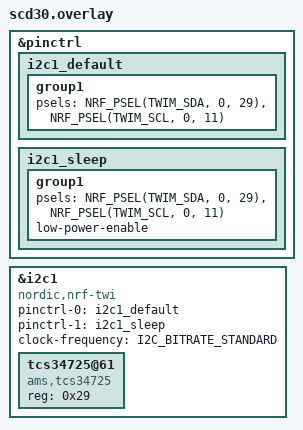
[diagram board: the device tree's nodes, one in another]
/*
 * Copyright (c) 2023 LSI-TEC
 *
 * SPDX-License-Identifier: Apache-2.0
 */

&pinctrl {
	i2c1_default: i2c1_default {
		group1 {
			psels = <NRF_PSEL(TWIM_SDA, 0, 29)>, // Verificar depois esses pinos
			        <NRF_PSEL(TWIM_SCL, 0, 11)>;
		};
	};

	i2c1_sleep: i2c1_sleep {
		group1 {
			psels = <NRF_PSEL(TWIM_SDA, 0, 29)>, 
			        <NRF_PSEL(TWIM_SCL, 0, 11)>;
			low-power-enable;
		};
	};
};

&i2c1 {
	compatible = "nordic,nrf-twi";
	status = "okay";

	pinctrl-0 = <&i2c1_default>;
	pinctrl-1 = <&i2c1_sleep>;
	pinctrl-names = "default", "sleep";

	clock-frequency = <I2C_BITRATE_STANDARD>;

	/* Color sensor */
	tcs34725@61 {
		compatible = "ams,tcs34725";
		reg = <0x29>;   /* Address of sensor */ // Verificar depois esse endereço // No codigo é feito 0x29 << 1 
		status = "okay";
		// sample-period = <2>; 
		//zephyr,deferred-init;
	};
};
